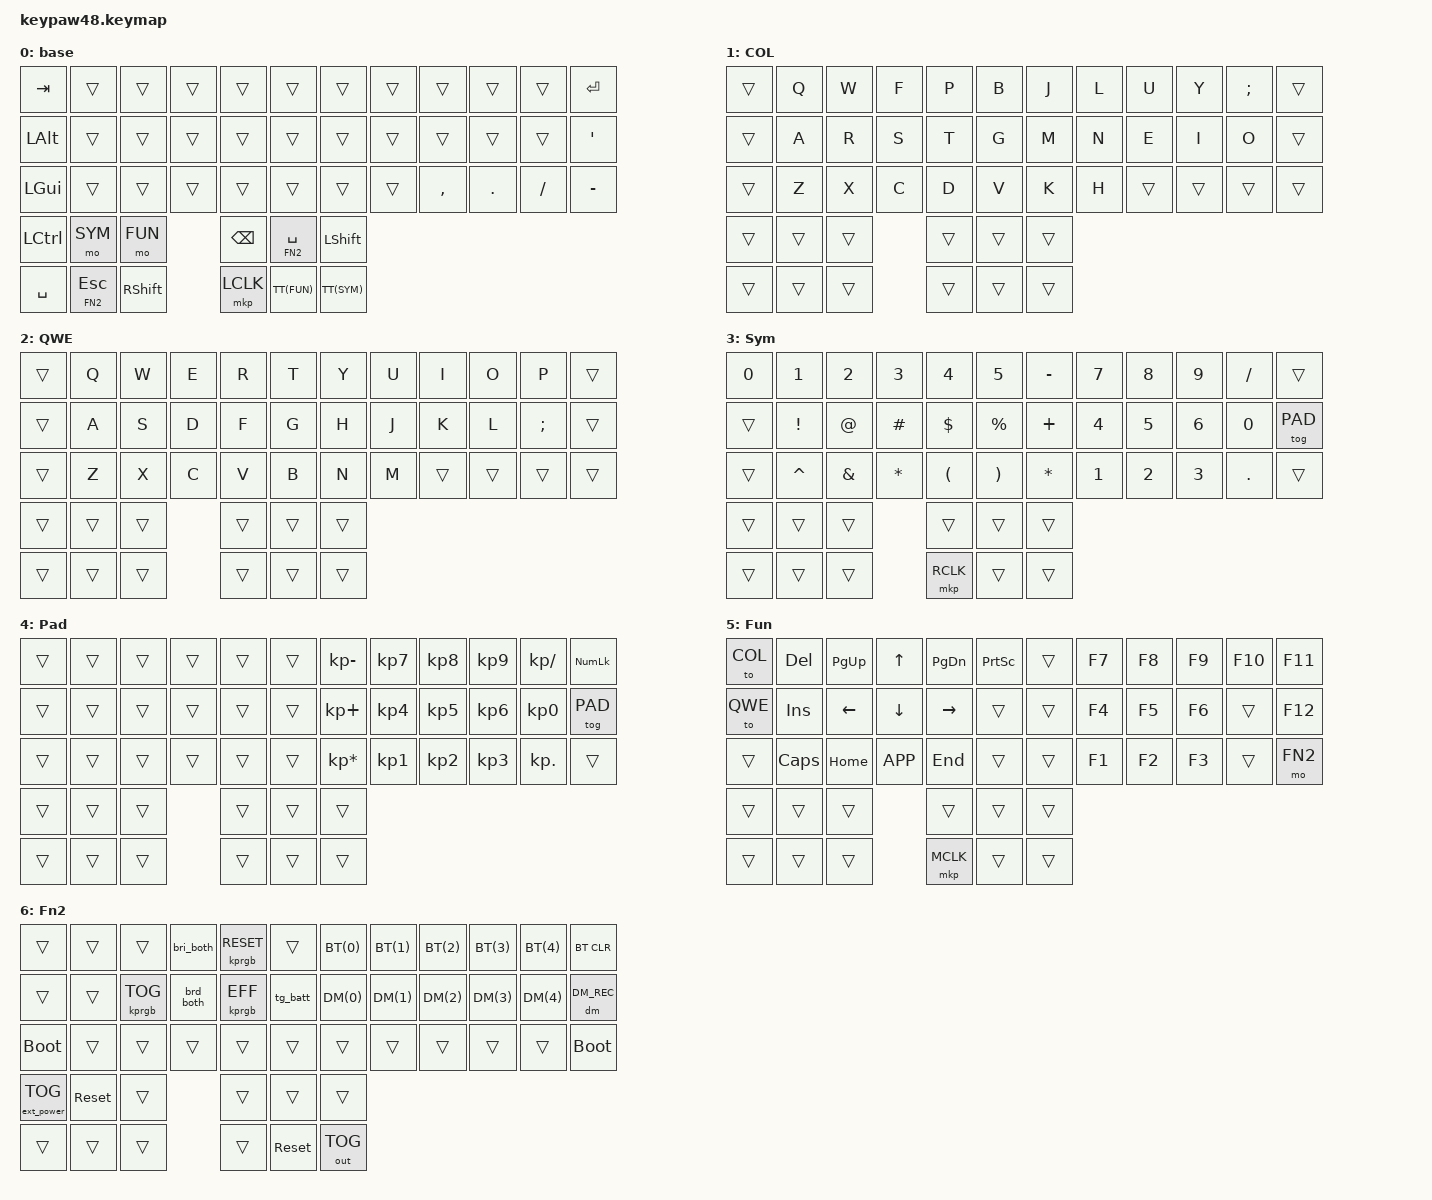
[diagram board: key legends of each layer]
/*
 * Copyright (c) 2026 The ZMK Contributors
 * SPDX-License-Identifier: MIT
 */

#include <behaviors.dtsi>
#include <dt-bindings/zmk/keys.h>
#include <dt-bindings/zmk/pointing.h>
#include <dt-bindings/zmk/bt.h>
#include <dt-bindings/zmk/ext_power.h>
#include <dt-bindings/zmk/outputs.h>
#include <dt-bindings/keypaw/rgb_matrix.h>
#include <dt-bindings/zmk/display_brightness.h>
#include <dt-bindings/zmk/dynamic_macro.h>
#include <dt-bindings/zmk/ft6236.h>

#define TT(layer) &tt layer layer
#define BT(profile) &bt BT_SEL profile
#define DM(slot) &dm DM_PLAY slot
#define CBB(name, keys, bind) name{timeout-ms=<50>;key-positions=<keys>;bindings=<bind>;}
#define CBK(name, keys, keycode) CBB(name, keys, &kp keycode)

// Layers
#define MOD 0
#define COL 1
#define QWE 2
#define SYM 3
#define PAD 4
#define FUN 5
#define FN2 6

&glidepoint_scroller {
    layers = <SYM>;
};

&glidepoint_cursor {
    layers = <FUN>;
};

/ {
    behaviors {
        jd_brt: jd_brt {
            compatible = "zmk,behavior-jd9613-brightness";
            #binding-cells = <1>;
        };

        dm: dm {
            compatible = "zmk,behavior-dynamic-macro";
            #binding-cells = <2>;
        };

        tt: layer_tap_toggle {
            compatible = "zmk,behavior-hold-tap";
            #binding-cells = <2>;
            flavor = "hold-preferred";
            tapping-term-ms = <200>;
            bindings = <&mo>, <&tog>;
        };
    };

    macros {
        bri_both: bri_both {
            compatible = "zmk,behavior-macro";
            #binding-cells = <0>;
            bindings = <&kprgb RGB_BRI &jd_brt JD_BRT_INC>;
        };
        brd_both: brd_both {
            compatible = "zmk,behavior-macro";
            #binding-cells = <0>;
            bindings = <&kprgb RGB_BRD &jd_brt JD_BRT_DEC>;
        };
    };

    boot_layers: boot-layers {
        compatible = "keypaw,boot-layers";
        layers = <COL>;
    };

    ft6236_gestures: ft6236_gestures {
        compatible = "zmk,input-processor-behaviors";
        #input-processor-cells = <0>;
        /* Gestures are held from recognition until the finger(s) lift, so a
         * momentary binding like &mkp LCLK is a real button hold: a one-finger
         * press-drag is a click-drag and a quick one-finger tap is a click. */
        codes = <
        FT6236_GESTURE_PRESS           FT6236_GESTURE_TWO_FINGER_TAP
        FT6236_GESTURE_UP              FT6236_GESTURE_DOWN
        FT6236_GESTURE_LEFT            FT6236_GESTURE_RIGHT
        FT6236_GESTURE_ZOOM_IN         FT6236_GESTURE_ZOOM_OUT
        FT6236_GESTURE_TWO_FINGER_UP   FT6236_GESTURE_TWO_FINGER_DOWN
        FT6236_GESTURE_TWO_FINGER_LEFT FT6236_GESTURE_TWO_FINGER_RIGHT
        >;
        bindings = <
        &mkp LCLK      &mkp RCLK
        &kp PG_UP      &kp PG_DN
        &kp HOME       &kp END
        &kp LC(EQUAL)  &kp LC(MINUS)
        &kp C_VOL_UP   &kp C_VOL_DN
        &kp C_PREV     &kp C_NEXT
        >;
    };

    axis_tap: axis_tap {
        compatible = "zmk,input-processor-axis-tap";
        #input-processor-cells = <0>;
        /* Tuning knobs: counts of trackball travel per arrow step */
        x-threshold = <32>;
        y-threshold = <160>;
        bindings = <&kp LEFT &kp RIGHT &kp UP &kp DOWN>;
    };

    combos {
        compatible = "zmk,combos";
        CBK(combo_esc, 15 16, ESC); // home row d+f
        CBK(combo_lpar, 16 17, LPAR); // home row f+g
        CBK(combo_rpar, 18 19, RPAR); // home row h+j
        CBK(combo_lbkt, 4 5, LBKT); // r+t
        CBK(combo_rbkt, 6 7, RBKT); // y+u
        CBK(combo_lbrc, 28 29, LBRC); // v+b
        CBK(combo_rbrc, 30 31, RBRC); // n+m

        CBK(combo_grave, 8 9, GRAVE); // i+o
        CBK(combo_tilde, 9 10, TILDE); // o+p
        CBK(combo_plus, 20 21, PLUS); // k+l
        CBK(combo_equal, 21 22, EQUAL); // l+;
        CBK(combo_bslh, 32 33, BSLH); // ,+.
        CBK(combo_pipe, 33 34, PIPE); // .+/
    };

    // See https://zmk.dev/docs/development/hardware-integration/new-shield#default-keymap.
    keymap {
        compatible = "zmk,keymap";

        base { // #0: basic modifiers
            bindings = <
            &kp TAB  &trans &trans &trans &trans &trans    &trans &trans &trans    &trans  &trans   &kp ENTER
            &kp LALT &trans &trans &trans &trans &trans    &trans &trans &trans    &trans  &trans   &kp SQT
            &kp LGUI &trans &trans &trans &trans &trans    &trans &trans &kp COMMA &kp DOT &kp FSLH &kp MINUS

            &kp LCTRL &mo SYM &mo FUN &kp BSPC &lt FN2 SPACE &kp LSHFT

            &kp SPACE &lt FN2 ESC &kp RSHFT &mkp LCLK TT(FUN) TT(SYM)
            >;
        };
        colemak_dh_layer { // #1
            display-name = "COL";
            bindings = <
            &trans &kp Q &kp W &kp F &kp P &kp B    &kp J &kp L &kp U  &kp Y  &kp SEMI &trans
            &trans &kp A &kp R &kp S &kp T &kp G    &kp M &kp N &kp E  &kp I  &kp O    &trans
            &trans &kp Z &kp X &kp C &kp D &kp V    &kp K &kp H &trans &trans &trans   &trans
            &trans &trans &trans &trans &trans &trans
            &trans &trans &trans &trans &trans &trans
            >;
        };
        qwerty_layer { // #2
            display-name = "QWE";
            bindings = <
            &trans &kp Q &kp W &kp E &kp R &kp T    &kp Y &kp U &kp I  &kp O  &kp P    &trans
            &trans &kp A &kp S &kp D &kp F &kp G    &kp H &kp J &kp K  &kp L  &kp SEMI &trans
            &trans &kp Z &kp X &kp C &kp V &kp B    &kp N &kp M &trans &trans &trans   &trans
            &trans &trans &trans &trans &trans &trans
            &trans &trans &trans &trans &trans &trans
            >;
        };

        sym_layer { // #3: Symbols/numbers
            display-name = "Sym";
            bindings = <
            &kp N0 &kp N1    &kp N2   &kp N3   &kp N4   &kp N5       &kp MINUS &kp N7 &kp N8 &kp N9 &kp FSLH &trans
            &trans &kp EXCL  &kp AT   &kp HASH &kp DLLR &kp PRCNT    &kp PLUS  &kp N4 &kp N5 &kp N6 &kp N0   &tog PAD
            &trans &kp CARET &kp AMPS &kp STAR &kp LPAR &kp RPAR     &kp STAR  &kp N1 &kp N2 &kp N3 &kp DOT  &trans

            &trans &trans &trans &trans &trans &trans    &trans &trans &trans &mkp RCLK &trans &trans
            >;
        };
        pad_layer { // #4: Keypad
            display-name = "Pad";
            bindings = <
            &trans &trans &trans &trans &trans &trans    &kp KP_MINUS    &kp KP_N7 &kp KP_N8 &kp KP_N9 &kp KP_SLASH &kp KP_NUM
            &trans &trans &trans &trans &trans &trans    &kp KP_PLUS     &kp KP_N4 &kp KP_N5 &kp KP_N6 &kp KP_N0    &tog PAD
            &trans &trans &trans &trans &trans &trans    &kp KP_MULTIPLY &kp KP_N1 &kp KP_N2 &kp KP_N3 &kp KP_DOT   &trans

            &trans &trans &trans &trans &trans &trans    &trans &trans &trans &trans &trans &trans
            >;
        };
        fun_layer { // #5: Function keys
            display-name = "Fun";
            bindings = <
            &to COL &kp DEL  &kp PG_UP &kp UP    &kp PG_DN &kp PSCRN    &trans &kp F7 &kp F8 &kp F9 &kp F10 &kp F11
            &to QWE &kp INS  &kp LEFT  &kp DOWN  &kp RIGHT &trans       &trans &kp F4 &kp F5 &kp F6 &trans  &kp F12
            &trans  &kp CAPS &kp HOME  &kp K_APP &kp END   &trans       &trans &kp F1 &kp F2 &kp F3 &trans  &mo FN2

            &trans &trans &trans &trans &trans &trans    &trans &trans &trans &mkp MCLK &trans &trans
            >;
        };

        fn2_layer { // #6: Keyboard & media controls
            display-name = "Fn2";
            bindings = <
            &trans &trans &trans         &bri_both &kprgb RGB_RESET &trans      BT(0) BT(1) BT(2) BT(3) BT(4) &bt BT_CLR
            &trans &trans &kprgb RGB_TOG &brd_both &kprgb RGB_EFF   &tg_batt    DM(0) DM(1) DM(2) DM(3) DM(4) &dm DM_REC

            &bootloader       &trans     &trans &trans &trans &trans    &trans &trans &trans &trans &trans     &bootloader
            &ext_power EP_TOG &sys_reset &trans &trans &trans &trans    &trans &trans &trans &trans &sys_reset &out OUT_TOG
            >;
        };
    };
};

&rgb_triggers {
    // A trigger is a condition plus the commands to run when it wins. The
    // condition is a reusable node: the one below also drives an overlay.
    trig_fn: trig_fn {
        compatible = "keypaw,rgb-trigger";
        condition = <&cond_layer_qwe>;
        bindings = <&fx_spectrum>;
    };

    // The catch-all; it must be the LAST child to act as the "else" rule.
    trig_default: trig_default {
        compatible = "keypaw,rgb-trigger";
        condition = <&cond_always>;
        bindings = <&fx_heatmap>;
    };
};

&rgb_conditions {
    // One condition per layer, shared by the trigger table above and the
    // overlays below. Layer state exists only on the central, so the overlays
    // are left at the default (central-evaluated): the central evaluates the
    // condition and pushes the on/off state to the peripheral.
    cond_layer_qwe: cond_layer_qwe {
        compatible = "keypaw,rgb-condition-layer";
        layer = <QWE>;
    };
    cond_layer_sym: cond_layer_sym {
        compatible = "keypaw,rgb-condition-layer";
        layer = <SYM>;
    };
    cond_layer_fun: cond_layer_fun {
        compatible = "keypaw,rgb-condition-layer";
        layer = <FUN>;
    };
    cond_layer_pad: cond_layer_pad {
        compatible = "keypaw,rgb-condition-layer";
        layer = <PAD>;
    };
    cond_layer_fn2: cond_layer_fn2 {
        compatible = "keypaw,rgb-condition-layer";
        layer = <FN2>;
    };
};

&rgb_overlays {
    layer_sym: layer_sym {
        compatible = "keypaw,rgb-overlay";
        condition = <&cond_layer_sym>;
        all-leds;
        effect = <&fx_breathe>;
    };
    layer_fun: layer_fun {
        compatible = "keypaw,rgb-overlay";
        condition = <&cond_layer_fun>;
        all-leds;
        fx_layer_fun {
            compatible = "keypaw,rgb-matrix-solid";
            #binding-cells = <0>;
            color = <0xFF8000>;
        };
    };
    layer_pad: layer_pad {
        compatible = "keypaw,rgb-overlay";
        condition = <&cond_layer_pad>;
        keys = <
            2  3  4   7  8  9
        13 14 15 16  19 20 21 22
           26 27 28  31 32 33
        >;
        fx_layer_pad {
            compatible = "keypaw,rgb-matrix-solid";
            #binding-cells = <0>;
            color = <0xFFFF00>;
        };
    };
    layer_fn2: layer_fn2 {
        compatible = "keypaw,rgb-overlay";
        condition = <&cond_layer_fn2>;
        all-leds;
        effect = <&fx_breathe>;
    };

    // The battery gauge, toggled by the nested `&tg_batt` behavior.
    batt: batt {
        compatible = "keypaw,rgb-overlay-battery";
        condition = <&cond_batt>;
        all-leds;
        color = <0x00FF00>;
    };
};
